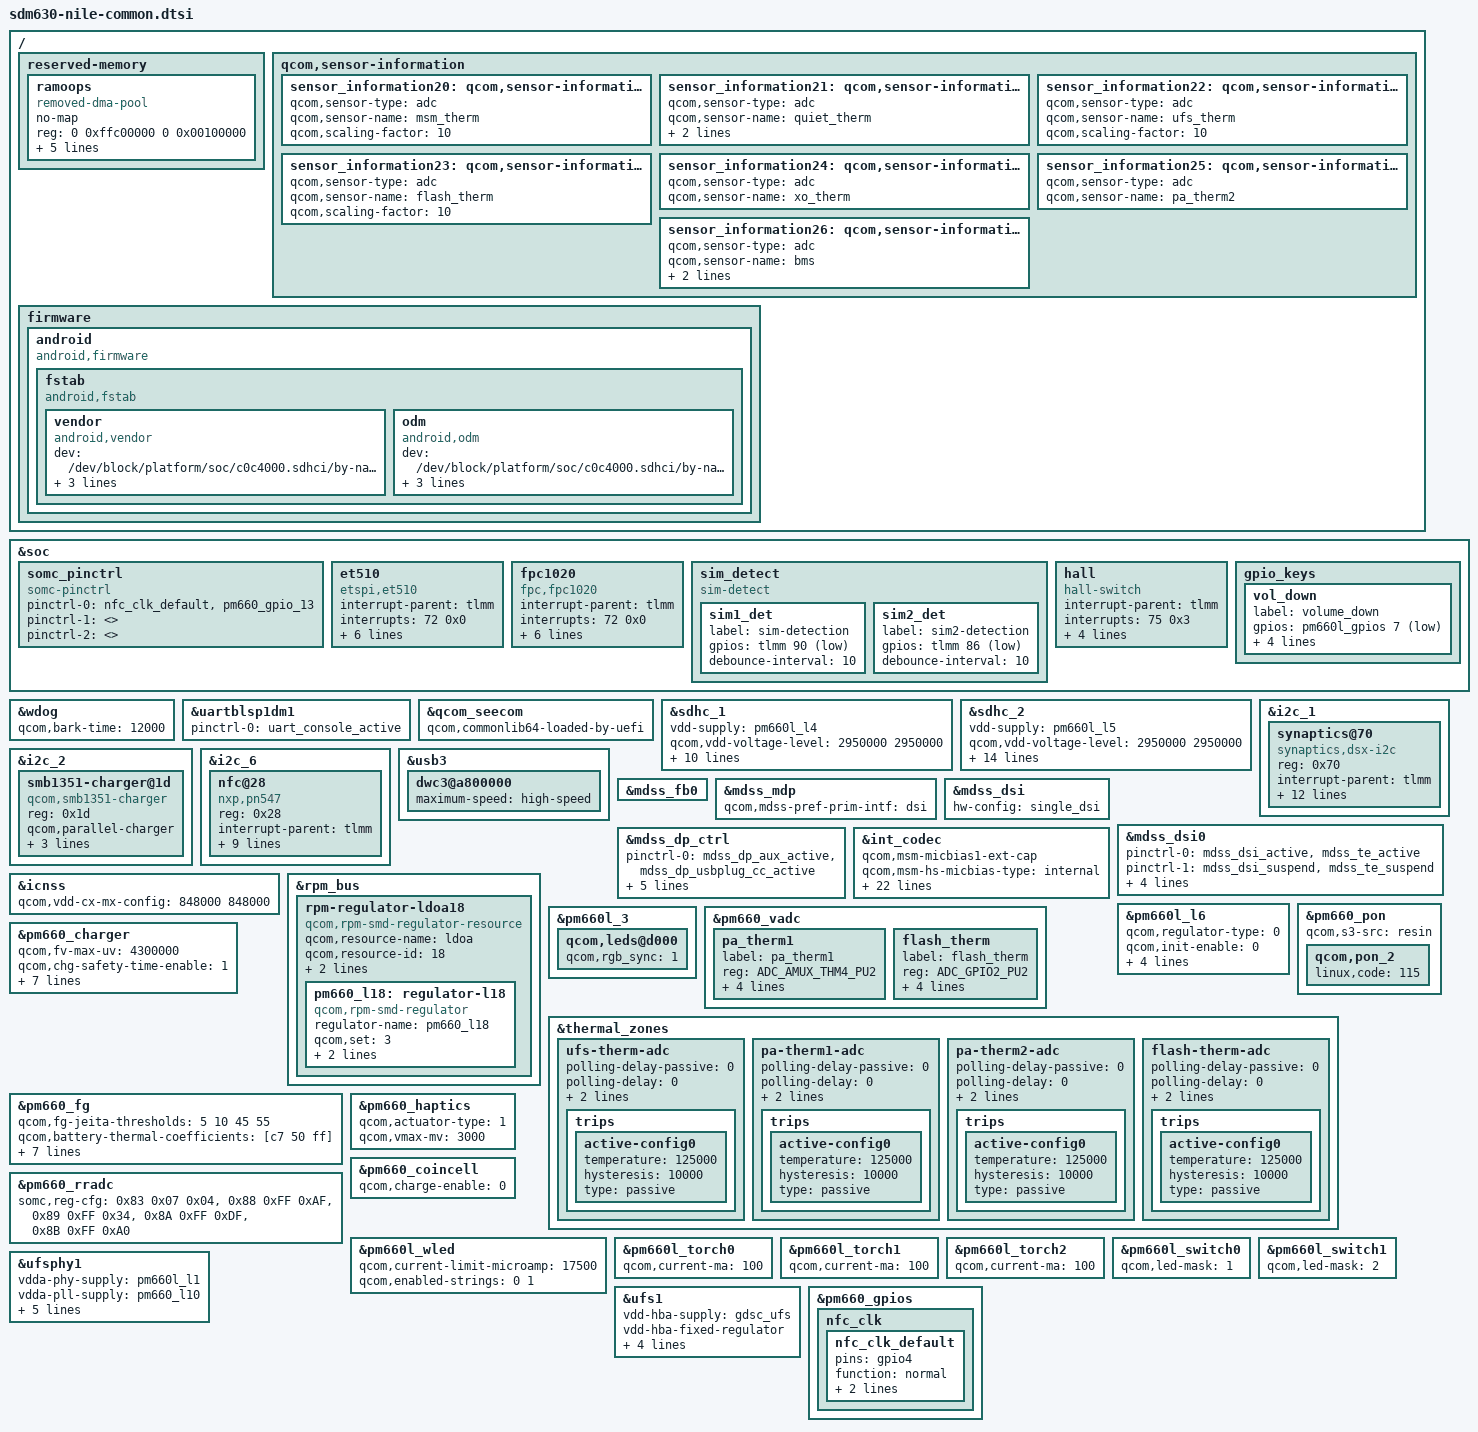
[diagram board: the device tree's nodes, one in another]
/* Copyright (c) 2016-2017, The Linux Foundation. All rights reserved.
 *
 * This program is free software; you can redistribute it and/or modify
 * it under the terms of the GNU General Public License version 2 and
 * only version 2 as published by the Free Software Foundation.
 *
 * This program is distributed in the hope that it will be useful,
 * but WITHOUT ANY WARRANTY; without even the implied warranty of
 * MERCHANTABILITY or FITNESS FOR A PARTICULAR PURPOSE.  See the
 * GNU General Public License for more details.
 */

#include "sdm630-nile_pinctrl.dtsi"
#include "sdm630-nile-common-thermal.dtsi"

/* Disable SMP2P Remote Debug for production */
#include "msm-rdbg-disable.dtsi"

/ {
	reserved-memory {
		ramoops {
			compatible = "removed-dma-pool", "ramoops";
			no-map;
			reg = <0 0xffc00000 0 0x00100000>;
			record-size = <0x10000>;
			console-size = <0x60000>;
			ftrace-size = <0x10000>;
			pmsg-size = <0x20000>;
			ecc-size = <16>;
		};
	};

	qcom,sensor-information {
		sensor_information20: qcom,sensor-information-20 { /* msm_therm */
			qcom,sensor-type =  "adc";
			qcom,sensor-name = "msm_therm";
			qcom,scaling-factor = <10>;
		};
		sensor_information21: qcom,sensor-information-21 { /* quiet_therm */
			qcom,sensor-type =  "adc";
			qcom,sensor-name = "quiet_therm";
			qcom,alias-name = "bl_therm";
			qcom,scaling-factor = <10>;
		};
		sensor_information22: qcom,sensor-information-22 { /* ufs_therm */
			qcom,sensor-type = "adc";
			qcom,sensor-name = "ufs_therm";
			qcom,scaling-factor = <10>;
		};
		sensor_information23: qcom,sensor-information-23 { /* flash_therm */
			qcom,sensor-type = "adc";
			qcom,sensor-name = "flash_therm";
			qcom,scaling-factor = <10>;
		};
		sensor_information24: qcom,sensor-information-24 { /* xo_therm */
			qcom,sensor-type = "adc";
			qcom,sensor-name = "xo_therm";
		};
		sensor_information25: qcom,sensor-information-25 { /* pa_therm2 */
			qcom,sensor-type = "adc";
			qcom,sensor-name = "pa_therm2";
		};
		sensor_information26: qcom,sensor-information-26 { /* bms */
			qcom,sensor-type = "adc";
			qcom,sensor-name = "bms";
			qcom,alias-name = "batt_therm";
			qcom,scaling-factor = <1000>;
		};
	};

	firmware: firmware {
		android {
			compatible = "android,firmware";
			fstab {
				compatible = "android,fstab";

				vendor {
					compatible = "android,vendor";
					dev = "/dev/block/platform/soc/c0c4000.sdhci/by-name/vendor";
					type = "ext4";
					mnt_flags = "ro,barrier=1";
					fsmgr_flags = "wait,slotselect";
					status = "ok";
				};

				odm {
					compatible = "android,odm";
					dev = "/dev/block/platform/soc/c0c4000.sdhci/by-name/oem";
					type = "ext4";
					mnt_flags = "ro,barrier=1";
					fsmgr_flags = "wait,slotselect";
					status = "ok";
				};
			};
		};
	};
};

&soc {
	somc_pinctrl: somc_pinctrl {
		compatible = "somc-pinctrl";
		pinctrl-names = "platform_common_default",
						"product_common_default",
						"variant_default";
		pinctrl-0 = <&nfc_clk_default &pm660_gpio_13>;

		/* If product common default setting is needed,
			fill pinctrl-1 value in <product>_common.dtsi */
		pinctrl-1 = <>;

		/* If variant specific default setting is needed,
			fill pinctrl-2 value in <variant>.dtsi */
		pinctrl-2 = <>;
	};

	et510 {
		compatible = "etspi,et510";
		interrupt-parent = <&tlmm>;
		interrupts = <72 0x0>;
		et51x,gpio_irq    = <&tlmm 72 0>;
		vdd_ana-supply = <&pm660l_l6>;
		et51x,check-sensor-type;

		pinctrl-names = "et51x_reset_reset",
			"et51x_reset_active",
			"et51x_irq_active";

		pinctrl-0 = <&msm_gpio_20>;
		pinctrl-1 = <&msm_gpio_20_output_high>;
		pinctrl-2 = <&msm_gpio_72>;
	};

	fpc1020 {
		compatible = "fpc,fpc1020";
		interrupt-parent = <&tlmm>;
		interrupts = <72 0x0>;
		fpc,gpio_rst    = <&tlmm 20 0x0>;
		fpc,gpio_irq    = <&tlmm 72 0x0>;
		vdd_ana-supply = <&pm660l_l6>;

		pinctrl-names = "fpc1145_reset_reset",
			"fpc1145_reset_active",
			"fpc1145_irq_active";

		pinctrl-0 = <&msm_gpio_20>;
		pinctrl-1 = <&msm_gpio_20_output_high>;
		pinctrl-2 = <&msm_gpio_72>;
	};

	sim_detect {
		compatible = "sim-detect";

		sim1_det {
			label = "sim-detection";
			gpios = <&tlmm 90 0x1>;
			debounce-interval = <10>;
		};

		sim2_det {
			label = "sim2-detection";
			gpios = <&tlmm 86 0x1>;
			debounce-interval = <10>;
		};
	};

	hall {
		compatible = "hall-switch";
		interrupt-parent = <&tlmm>;
		interrupts = <75 0x3>;
		//vddio-supply = <&pm660l_l14>;
		linux,gpio-int = <&tlmm 75 0x1>;
		linux,wakeup;
		linux,min-uv = <1700000>;
		linux,max-uv = <1900000>;
	};

	gpio_keys {
		/delete-node/ vol_up;
		vol_down {
			label = "volume_down";
			gpios = <&pm660l_gpios 7 0x1>;
			linux,input-type = <1>;
			linux,code = <114>;
			gpio-key,wakeup;
			debounce-interval = <15>;
		};
	};
};

&wdog {
	qcom,bark-time = <12000>;
};

&uartblsp1dm1 {
	status = "ok";
	pinctrl-names = "default";
	pinctrl-0 = <&uart_console_active>;
};

&qcom_seecom {
	qcom,commonlib64-loaded-by-uefi;
};

&sdhc_1 {
	/* device core power supply */
	vdd-supply = <&pm660l_l4>;
	qcom,vdd-voltage-level = <2950000 2950000>;
	qcom,vdd-current-level = <200 570000>;

	/* device communication power supply */
	vdd-io-supply = <&pm660_l8>;
	qcom,vdd-io-always-on;
	qcom,vdd-io-lpm-sup;
	qcom,vdd-io-voltage-level = <1800000 1800000>;
	qcom,vdd-io-current-level = <110 325000>;

	pinctrl-names = "active", "sleep";
	pinctrl-0 = <&sdc1_clk_on &sdc1_cmd_on &sdc1_data_on &sdc1_rclk_on>;
	pinctrl-1 = <&sdc1_clk_off &sdc1_cmd_off &sdc1_data_off &sdc1_rclk_off>;

	status = "ok";
};

&sdhc_2 {
	/* device core power supply */
	vdd-supply = <&pm660l_l5>;
	qcom,vdd-voltage-level = <2950000 2950000>;
	qcom,vdd-current-level = <15000 800000>;

	/* device communication power supply */
	vdd-io-supply = <&pm660l_l2>;
	qcom,vdd-io-voltage-level = <1800000 2950000>;
	qcom,vdd-io-current-level = <200 22000>;

	pinctrl-names = "active", "sleep";
	pinctrl-0 = <&sdc2_clk_on &sdc2_cmd_on &sdc2_data_on &sdc2_cd_on>;
	pinctrl-1 = <&sdc2_clk_off &sdc2_cmd_off &sdc2_data_off &sdc2_cd_off>;

	#address-cells = <0>;
	interrupt-parent = <&sdhc_2>;
	interrupts = <0 1 2>;
	#interrupt-cells = <1>;
	interrupt-map-mask = <0xffffffff>;
	interrupt-map = <0 &intc 0 0 125 0
			1 &intc 0 0 221 0
			2 &tlmm 54 0>;
	interrupt-names = "hc_irq", "pwr_irq", "status_irq";
	cd-gpios = <&tlmm 54 0x1>;

	status = "ok";
};

&i2c_1 {
	status = "okay";

	synaptics@70 {
		compatible = "synaptics,dsx-i2c";
		reg = <0x70>;
		interrupt-parent = <&tlmm>;
		interrupts = <45 0x2008>;
		pinctrl-names = "pmx_ts_active", "pmx_ts_suspend";
		pinctrl-0 = <&ts_lcd_id_active>;
		pinctrl-1 = <&ts_lcd_id_suspend>;
		synaptics,pwr-reg-name = "avdd";
		synaptics,bus-reg-name = "vdd";
		synaptics,ub-i2c-addr = <0x20>;
		synaptics,irq-gpio = <&tlmm 45 0x2008>; /* IRQF_ONESHOT | IRQF_TRIGGER_LOW */
		synaptics,irq-on-state = <0>;
		synaptics,power-delay-ms = <200>;
		synaptics,reset-delay-ms = <200>;
		synaptics,reset-on-state = <0>;
		synaptics,reset-active-ms = <20>;
	};
};

&i2c_2 {
	status = "ok";
	smb1351-charger@1d {
		compatible = "qcom,smb1351-charger";
		reg = <0x1d>;
		qcom,parallel-charger;
		qcom,float-voltage-mv = <4400>;
		qcom,recharge-mv = <100>;
		qcom,parallel-en-pin-polarity = <1>;
	};
};

&i2c_6 {
	/delete-node/ nq@28;
	nfc@28 {
		compatible = "nxp,pn547";
		reg = <0x28>;
		interrupt-parent = <&tlmm>;
		interrupts = <28 0>;
		nxp,irq_gpio = <&tlmm 28 0>;
		nxp,ven = <&tlmm 29 0x01>;
		nxp,dwld_en = <&tlmm 30 0>;
		// Note: esepwr is used only by TEE. Kept for HW reference.
		//nxp,pvdd_en = <&tlmm 31 0>;
		qcom,clk-src = "BBCLK3";
		qcom,clk-gpio = <&pm660_gpios 4 0x00>;
		clock-names = "nfc_clk";
		clocks = <&clock_rpmcc RPM_SMD_LN_BB_CLK3_PIN>;
		pinctrl-names = "pn547-active", "pn547-inactive";
		pinctrl-0 = <&nfc_int_active &nfc_enable_active>;
		pinctrl-1 = <&nfc_int_suspend &nfc_enable_suspend>;
	};
};

&usb3 {
	dwc3@a800000 {
		maximum-speed = "high-speed";
		/delete-property/ snps,has-lpm-erratum;
	};
};

&mdss_fb0 {
	/delete-node/ qcom,cont-splash-memory;
};

&mdss_mdp {
	qcom,mdss-pref-prim-intf = "dsi";
};

&mdss_dsi {
	hw-config = "single_dsi";
};

&mdss_dsi0 {
	pinctrl-names = "mdss_default", "mdss_sleep";
	pinctrl-0 = <&mdss_dsi_active &mdss_te_active>;
	pinctrl-1 = <&mdss_dsi_suspend &mdss_te_suspend>;
	qcom,display-id = "primary";
	qcom,mdss-fb-map-prim = <&mdss_fb0>;
	qcom,platform-reset-gpio = <&tlmm 53 0>;
	qcom,platform-te-gpio = <&tlmm 59 0>;
};

&mdss_dp_ctrl {
	pinctrl-names = "mdss_dp_active", "mdss_dp_sleep";
	pinctrl-0 = <&mdss_dp_aux_active &mdss_dp_usbplug_cc_active>;
	pinctrl-1 = <&mdss_dp_aux_suspend &mdss_dp_usbplug_cc_suspend>;
	qcom,aux-en-gpio = <&tlmm 55 0>;
	qcom,aux-sel-gpio = <&tlmm 56 0>;
	qcom,usbplug-cc-gpio = <&tlmm 58 0>;
};

&int_codec {
	status = "ok";
	/delete-property/ qcom,msm-micbias2-ext-cap;
	qcom,msm-micbias1-ext-cap;
	qcom,msm-hs-micbias-type = "internal";

	qcom,wsa-max-devs = <1>;
	qcom,wsa-aux-dev-prefix = "SpkrLeft", "SpkrLeft",
				  "SpkrLeft", "SpkrLeft";

	qcom,audio-routing =
		"RX_BIAS", "INT_MCLK0",
		"SPK_RX_BIAS", "INT_MCLK0",
		"INT_LDO_H", "INT_MCLK0",
		"RX_I2S_CLK", "INT_MCLK0",
		"TX_I2S_CLK", "INT_MCLK0",
		"MIC BIAS External", "Handset Mic",
		"MIC BIAS Internal2", "Headset Mic",
		"MIC BIAS External", "Secondary Mic",
		"AMIC1", "MIC BIAS External",
		"AMIC2", "MIC BIAS Internal2",
		"AMIC3", "MIC BIAS External",
		"DMIC1", "MIC BIAS External",
		"MIC BIAS External", "Digital Mic1",
		"DMIC2", "MIC BIAS External",
		"MIC BIAS External", "Digital Mic2",
		"DMIC3", "MIC BIAS External",
		"MIC BIAS External", "Digital Mic3",
		"DMIC4", "MIC BIAS External",
		"MIC BIAS External", "Digital Mic4",
		"SpkrLeft IN", "SPK1 OUT",
		"SpkrRight IN", "SPK2 OUT",
		"PDM_IN_RX1", "PDM_OUT_RX1",
		"PDM_IN_RX2", "PDM_OUT_RX2",
		"PDM_IN_RX3", "PDM_OUT_RX3",
		"ADC1_IN", "ADC1_OUT",
		"ADC2_IN", "ADC2_OUT",
		"ADC3_IN", "ADC3_OUT";
};

&icnss {
	qcom,vdd-cx-mx-config = <848000 848000>;
};

&rpm_bus {
	rpm-regulator-ldoa18 {
		compatible = "qcom,rpm-smd-regulator-resource";
		qcom,resource-name = "ldoa";
		qcom,resource-id = <18>;
		qcom,regulator-type = <0>;
		qcom,regulator-hw-type = "pmic4-ldo";
		status = "okay";
		pm660_l18: regulator-l18 {
			compatible = "qcom,rpm-smd-regulator";
			regulator-name = "pm660_l18";
			qcom,set = <3>;
			regulator-min-microvolt = <1800000>;
			regulator-max-microvolt = <1800000>;
			status = "okay";
		};
	};
};
&pm660l_l6 {
	qcom,regulator-type = <0>;  /* LDO */
	qcom,init-enable = <0>;
	qcom,init-ldo-mode = <1>;
	qcom,init-pin-ctrl-enable = <0>;
	qcom,init-pin-ctrl-mode = <0>;
	qcom,init-voltage = <3300000>;
};

/* PM660 */
&pm660_pon {
	/delete-property/ kpdpwr-sw-debounce;
	qcom,s3-src = "resin";
	qcom,pon_2 {
		linux,code = <115>;
	};
};

&pm660l_3 {
	qcom,leds@d000 {
		status = "okay";
		qcom,rgb_sync = <1>;
	};
};

&pm660_vadc {
	#thermal-sensor-cells = <1>;

	pa_therm1 {
		label = "pa_therm1";
		reg = <ADC_AMUX_THM4_PU2>;
		qcom,ratiometric;
		qcom,hw-settle-time = <200>;
		qcom,decimation = <1024>;
		qcom,pre-scaling = <1 1>;
	};

	flash_therm {
		label = "flash_therm";
		reg = <ADC_GPIO2_PU2>;
		qcom,ratiometric;
		qcom,hw-settle-time = <200>;
		qcom,decimation = <1024>;
		qcom,pre-scaling = <1 1>;
	};
};

&thermal_zones {
	ufs-therm-adc {
		polling-delay-passive = <0>;
		polling-delay = <0>;
		thermal-sensors = <&pm660_vadc 0x4e>;
		thermal-governor = "user_space";

		trips {
			active-config0 {
				temperature = <125000>;
				hysteresis = <10000>;
				type = "passive";
			};
		};
	};

	pa-therm1-adc {
		polling-delay-passive = <0>;
		polling-delay = <0>;
		thermal-sensors = <&pm660_vadc 0x4d>;
		thermal-governor = "user_space";

		trips {
			active-config0 {
				temperature = <125000>;
				hysteresis = <10000>;
				type = "passive";
			};
		};
	};

	pa-therm2-adc {
		polling-delay-passive = <0>;
		polling-delay = <0>;
		thermal-sensors = <&pm660_vadc 0x50>;
		thermal-governor = "user_space";

		trips {
			active-config0 {
				temperature = <125000>;
				hysteresis = <10000>;
				type = "passive";
			};
		};
	};

	flash-therm-adc {
		polling-delay-passive = <0>;
		polling-delay = <0>;
		thermal-sensors = <&pm660_vadc 0x53>;
		thermal-governor = "user_space";

		trips {
			active-config0 {
				temperature = <125000>;
				hysteresis = <10000>;
				type = "passive";
			};
		};
	};
};

&pm660_charger {
	qcom,fv-max-uv = <4300000>;
	qcom,chg-safety-time-enable = <1>;
	qcom,chg-usb-pre-safety-time = <1>;
	qcom,chg-ac-pre-safety-time = <1>;
	qcom,chg-usb-fast-safety-time = <2>;
	qcom,chg-ac-fast-safety-time = <2>;
	qcom,float-option = <2>;
	qcom,thermal-mitigation = <2400000 1000000 500000 200000>;
};

&pm660_fg {
	qcom,fg-jeita-thresholds = <5 10 45 55>;
	qcom,battery-thermal-coefficients = [c7 50 ff];
	qcom,fg-sys-term-current = <(-200)>;
	qcom,fg-cutoff-voltage = <3400>;
	qcom,fg-rsense-sel = <0>;
	qcom,fg-chg-term-current = <150>;
	qcom,fg-force-load-profile;
	qcom,slope-limit-temp-threshold = <10>;
	qcom,slope-limit-coeffs = <1 1 1 1>;
};

&pm660_rradc {
	somc,reg-cfg =
	      /* addr mask value */
	      <0x83 0x07 0x04>, /* FG_ADC_RR_AUX_THERM_CFG */
	      <0x88 0xFF 0xAF>, /* FG_ADC_RR_AUX_THERM_C1 */
	      <0x89 0xFF 0x34>, /* FG_ADC_RR_AUX_THERM_C2 */
	      <0x8A 0xFF 0xDF>, /* FG_ADC_RR_AUX_THERM_C3 */
	      <0x8B 0xFF 0xA0>; /* FG_ADC_RR_AUX_THERM_HALF_RANGE */
};

&pm660_haptics {
	qcom,actuator-type = <1>;
	qcom,vmax-mv = <3000>;
};

&pm660_coincell {
	qcom,charge-enable = <0>;
};

/* PM660L */
&pm660l_wled {
	qcom,current-limit-microamp = <17500>;
	qcom,enabled-strings = <0 1>;
};

&pm660l_torch0 {
	qcom,current-ma = <100>;
};

&pm660l_torch1 {
	qcom,current-ma = <100>;
};

&pm660l_torch2 {
	qcom,current-ma = <100>;
};

&pm660l_switch0 {
	qcom,led-mask = <1>;
};

&pm660l_switch1 {
	qcom,led-mask = <2>;
};

&ufsphy1 {
	vdda-phy-supply = <&pm660l_l1>;
	vdda-pll-supply = <&pm660_l10>;
	vddp-ref-clk-supply = <&pm660_l1>;
	vdda-phy-max-microamp = <51400>;
	vdda-pll-max-microamp = <14200>;
	vddp-ref-clk-max-microamp = <100>;
	vddp-ref-clk-always-on;
	status = "ok";
};

&ufs1 {
	vdd-hba-supply = <&gdsc_ufs>;
	vdd-hba-fixed-regulator;
	vcc-supply = <&pm660l_l4>;
	vccq2-supply = <&pm660_l8>;
	vcc-max-microamp = <500000>;
	vccq2-max-microamp = <600000>;
	status = "ok";
};

&pm660_gpios {
	/* GPIO 4 (NFC_CLK_REQ) */
	nfc_clk {
		nfc_clk_default: nfc_clk_default {
			pins = "gpio4";
			function = "normal";
			input-enable;
			power-source = <1>;
		};
	};
};
